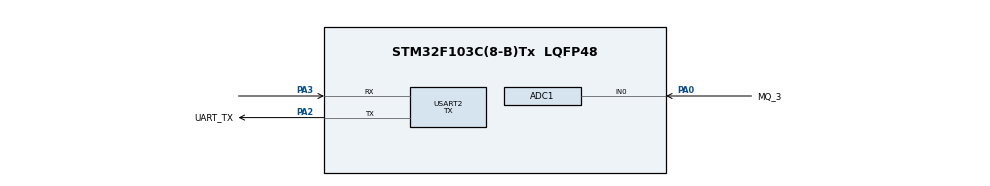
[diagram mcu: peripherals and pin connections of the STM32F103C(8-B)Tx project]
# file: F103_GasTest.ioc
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ADC1.Channel-2\#ChannelRegularConversion=ADC_CHANNEL_0
ADC1.ExternalTrigConv=ADC_EXTERNALTRIGCONV_T3_TRGO
ADC1.NbrOfConversionFlag=1
ADC1.Rank-2\#ChannelRegularConversion=1
ADC1.SamplingTime-2\#ChannelRegularConversion=ADC_SAMPLETIME_28CYCLES_5
ADC1.master=1
Dma.ADC1.1.Direction=DMA_PERIPH_TO_MEMORY
Dma.ADC1.1.Instance=DMA1_Channel1
Dma.ADC1.1.MemDataAlignment=DMA_MDATAALIGN_HALFWORD
Dma.ADC1.1.MemInc=DMA_MINC_ENABLE
Dma.ADC1.1.Mode=DMA_CIRCULAR
Dma.ADC1.1.PeriphDataAlignment=DMA_PDATAALIGN_HALFWORD
Dma.ADC1.1.PeriphInc=DMA_PINC_DISABLE
Dma.ADC1.1.Priority=DMA_PRIORITY_LOW
Dma.Request0=USART2_TX
Dma.Request1=ADC1
Dma.USART2_TX.0.Direction=DMA_MEMORY_TO_PERIPH
Dma.USART2_TX.0.Instance=DMA1_Channel7
Dma.USART2_TX.0.MemDataAlignment=DMA_MDATAALIGN_HALFWORD
Dma.USART2_TX.0.MemInc=DMA_MINC_ENABLE
Dma.USART2_TX.0.Mode=DMA_NORMAL
Dma.USART2_TX.0.PeriphDataAlignment=DMA_PDATAALIGN_BYTE
Dma.USART2_TX.0.PeriphInc=DMA_PINC_DISABLE
Dma.USART2_TX.0.Priority=DMA_PRIORITY_LOW
Mcu.Family=STM32F1
Mcu.Name=STM32F103C(8-B)Tx
Mcu.Package=LQFP48
NVIC.ADC1_2_IRQn=true\:0\:0\:false\:false\:true\:true\:true\:true
NVIC.DMA1_Channel1_IRQn=true\:0\:0\:false\:false\:true\:false\:true\:true
NVIC.DMA1_Channel7_IRQn=true\:0\:0\:false\:false\:true\:false\:true\:true
NVIC.PriorityGroup=NVIC_PRIORITYGROUP_4
NVIC.RCC_IRQn=true\:0\:0\:false\:false\:true\:true\:false\:true
NVIC.TIM3_IRQn=true\:0\:0\:false\:false\:true\:true\:true\:true
NVIC.USART2_IRQn=true\:0\:0\:false\:false\:true\:true\:true\:true
PA0-WKUP.GPIO_Label=MQ_3
PA0-WKUP.Signal=ADCx_IN0
PA13.GPIO_Label=SYS_JTMS
PA13.Mode=Serial_Wire
PA13.Signal=SYS_JTMS-SWDIO
PA14.GPIO_Label=SYS_JTCK
PA14.Mode=Serial_Wire
PA14.Signal=SYS_JTCK-SWCLK
PA2.GPIO_Label=UART_TX
PA2.GPIO_Mode=GPIO_MODE_AF_PP
PA2.Mode=Asynchronous
PA2.Signal=USART2_TX
PA3.Mode=Asynchronous
PA3.Signal=USART2_RX
ProjectManager.HeapSize=0x200
ProjectManager.StackSize=0x400
ProjectManager.TargetToolchain=STM32CubeIDE
RCC.APB1Freq_Value=8000000
RCC.APB2Freq_Value=8000000
SH.ADCx_IN0.0=ADC1_IN0,IN0
TIM3.Period=999
TIM3.Prescaler=71
TIM3.TIM_MasterOutputTrigger=TIM_TRGO_UPDATE
USART2.Mode=MODE_TX
USART2.VirtualMode=VM_ASYNC
VP_TIM3_VS_ClockSourceINT.Mode=Internal
board=custom

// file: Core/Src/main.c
/* USER CODE BEGIN Header */
/**
  ******************************************************************************
  * @file           : main.c
  * @brief          : Main program body
  ******************************************************************************
  * @attention
  *
  * Copyright (c) 2026 STMicroelectronics.
  * All rights reserved.
  *
  * This software is licensed under terms that can be found in the LICENSE file
  * in the root directory of this software component.
  * If no LICENSE file comes with this software, it is provided AS-IS.
  *
  ******************************************************************************
  */
/* USER CODE END Header */
#include "main.h"
#include "string.h"
/* USER CODE BEGIN Includes */
#include <stdint.h>
#include "stdio.h"
/* USER CODE END Includes */

/* USER CODE BEGIN PTD */
#define RB_SIZE			8
#define FRAME_HEADER    0xAA
#define CMD_MQ3_VALUE   0x01
#define MAX_DATA_LEN    8

typedef struct {
	uint16_t 	buf[RB_SIZE];
	uint8_t 	head;
	uint8_t		tail;
	uint8_t		count;
} RingBuffer_t;

/* USER CODE END PTD */

ADC_HandleTypeDef hadc1;
DMA_HandleTypeDef hdma_adc1;

TIM_HandleTypeDef htim3;

UART_HandleTypeDef huart2;
DMA_HandleTypeDef hdma_usart2_tx;

/* USER CODE BEGIN PV */

static volatile uint16_t adcRawValue   = 0;
static volatile uint8_t  newSampleFlag = 0;
static RingBuffer_t adcRing = {0};
static volatile uint8_t uartTxBusy = 0;
/* USER CODE END PV */

void SystemClock_Config(void);
static void MX_GPIO_Init(void);
static void MX_DMA_Init(void);
static void MX_USART2_UART_Init(void);
static void MX_TIM3_Init(void);
static void MX_ADC1_Init(void);

/* USER CODE BEGIN 0 */

/*======================Ring Buffer + Interference Filter============================*/
static void RB_Push(RingBuffer_t *rb, uint16_t value) {
	if (rb->count == RB_SIZE) {
		rb->tail = (rb->tail + 1) % RB_SIZE;
		rb->count--;
	}
	rb->buf[rb->head] = value;
	rb->head = (rb->head + 1) % RB_SIZE;
	rb->count++;
}

static uint16_t RB_Average(RingBuffer_t *rb) {
	if (rb->count == 0)
		return 0;
	uint32_t sum = 0;
	for (uint8_t i = 0; i < rb->count; i++) {
		uint8_t idx = (rb->tail + i) % RB_SIZE;
		sum += rb->buf[idx];
	}
	return (sum / rb->count);
}

/*================ADC + DMA=============================*/
void HAL_ADC_ConvCpltCallback(ADC_HandleTypeDef* hadc){
	if (hadc->Instance == ADC1){
		RB_Push(&adcRing, adcRawValue);
		newSampleFlag = 1;
	}
	HAL_GPIO_TogglePin(GPIOC, GPIO_PIN_13);
}

/* ================= UART TX (DMA) ================= */

static inline uint8_t CalculateCRC(const uint8_t *data, uint8_t len)
{
    uint8_t crc = 0;
    for (uint8_t i = 0; i < len; i++)
        crc ^= data[i];
    return crc;
}

void HAL_UART_TxCpltCallback(UART_HandleTypeDef *huart){
	if(huart->Instance == USART2){
		uartTxBusy = 0;
	}
}

static uint8_t BuildMQ3Frame(uint8_t *txBuf, uint16_t adcValue)
{
    uint8_t idx = 0;
    txBuf[idx++] = FRAME_HEADER;
    txBuf[idx++] = CMD_MQ3_VALUE;
    txBuf[idx++] = 2;
    txBuf[idx++] = adcValue;         /* LSB */
    txBuf[idx++] = (adcValue >> 8) & 0xFF;  /* MSB */

    uint8_t crc = CalculateCRC(&txBuf[1], idx - 1);
    txBuf[idx++] = crc;

    return idx;
}

static void SendMQ3Frame(uint16_t avgValue)
{
    static uint8_t txBuf[6];

    if (uartTxBusy) return;

    uint16_t len =  BuildMQ3Frame(txBuf, avgValue);
    uartTxBusy = 1;
    HAL_UART_Transmit_DMA(&huart2, txBuf, len);
}

/* USER CODE END 0 */

int main(void)
{

  /* MCU Configuration--------------------------------------------------------*/

  /* Reset of all peripherals, Initializes the Flash interface and the Systick. */
  HAL_Init();

  /* Configure the system clock */
  SystemClock_Config();

  /* Initialize all configured peripherals */
  MX_GPIO_Init();
  MX_DMA_Init();
  MX_USART2_UART_Init();
  MX_TIM3_Init();
  MX_ADC1_Init();
  /* USER CODE BEGIN 2 */

	HAL_ADC_Start_DMA(&hadc1, (uint32_t*) &adcRawValue, 1);
	HAL_TIM_Base_Start(&htim3);

  /* USER CODE END 2 */

  /* Infinite loop */
  while (1)
  {

    /* USER CODE BEGIN 3 */
	      static uint32_t sendCounter = 0;

	      if (newSampleFlag)
	      {
	          newSampleFlag = 0;
	          sendCounter++;

	          if (sendCounter >= 10)
	          {
	              sendCounter = 0;
	              uint16_t avg = RB_Average(&adcRing);
	              SendMQ3Frame(avg);
	          }
	      }
	  }

  /* USER CODE END 3 */
}

void SystemClock_Config(void)
{
  RCC_OscInitTypeDef RCC_OscInitStruct = {0};
  RCC_ClkInitTypeDef RCC_ClkInitStruct = {0};
  RCC_PeriphCLKInitTypeDef PeriphClkInit = {0};

  /** Initializes the RCC Oscillators according to the specified parameters
  * in the RCC_OscInitTypeDef structure.
  */
  RCC_OscInitStruct.OscillatorType = RCC_OSCILLATORTYPE_HSI;
  RCC_OscInitStruct.HSIState = RCC_HSI_ON;
  RCC_OscInitStruct.HSICalibrationValue = RCC_HSICALIBRATION_DEFAULT;
  RCC_OscInitStruct.PLL.PLLState = RCC_PLL_NONE;
  if (HAL_RCC_OscConfig(&RCC_OscInitStruct) != HAL_OK)
  {
    Error_Handler();
  }

  /** Initializes the CPU, AHB and APB buses clocks
  */
  RCC_ClkInitStruct.ClockType = RCC_CLOCKTYPE_HCLK|RCC_CLOCKTYPE_SYSCLK
                              |RCC_CLOCKTYPE_PCLK1|RCC_CLOCKTYPE_PCLK2;
  RCC_ClkInitStruct.SYSCLKSource = RCC_SYSCLKSOURCE_HSI;
  RCC_ClkInitStruct.AHBCLKDivider = RCC_SYSCLK_DIV1;
  RCC_ClkInitStruct.APB1CLKDivider = RCC_HCLK_DIV1;
  RCC_ClkInitStruct.APB2CLKDivider = RCC_HCLK_DIV1;

  if (HAL_RCC_ClockConfig(&RCC_ClkInitStruct, FLASH_LATENCY_0) != HAL_OK)
  {
    Error_Handler();
  }
  PeriphClkInit.PeriphClockSelection = RCC_PERIPHCLK_ADC;
  PeriphClkInit.AdcClockSelection = RCC_ADCPCLK2_DIV2;
  if (HAL_RCCEx_PeriphCLKConfig(&PeriphClkInit) != HAL_OK)
  {
    Error_Handler();
  }
}

static void MX_ADC1_Init(void)
{

  ADC_ChannelConfTypeDef sConfig = {0};

  /** Common config
  */
  hadc1.Instance = ADC1;
  hadc1.Init.ScanConvMode = ADC_SCAN_DISABLE;
  hadc1.Init.ContinuousConvMode = DISABLE;
  hadc1.Init.DiscontinuousConvMode = DISABLE;
  hadc1.Init.ExternalTrigConv = ADC_EXTERNALTRIGCONV_T3_TRGO;
  hadc1.Init.DataAlign = ADC_DATAALIGN_RIGHT;
  hadc1.Init.NbrOfConversion = 1;
  if (HAL_ADC_Init(&hadc1) != HAL_OK)
  {
    Error_Handler();
  }

  /** Configure Regular Channel
  */
  sConfig.Channel = ADC_CHANNEL_0;
  sConfig.Rank = ADC_REGULAR_RANK_1;
  sConfig.SamplingTime = ADC_SAMPLETIME_28CYCLES_5;
  if (HAL_ADC_ConfigChannel(&hadc1, &sConfig) != HAL_OK)
  {
    Error_Handler();
  }

}

static void MX_TIM3_Init(void)
{

  TIM_ClockConfigTypeDef sClockSourceConfig = {0};
  TIM_MasterConfigTypeDef sMasterConfig = {0};

  htim3.Instance = TIM3;
  htim3.Init.Prescaler = 71;
  htim3.Init.CounterMode = TIM_COUNTERMODE_UP;
  htim3.Init.Period = 999;
  htim3.Init.ClockDivision = TIM_CLOCKDIVISION_DIV1;
  htim3.Init.AutoReloadPreload = TIM_AUTORELOAD_PRELOAD_DISABLE;
  if (HAL_TIM_Base_Init(&htim3) != HAL_OK)
  {
    Error_Handler();
  }
  sClockSourceConfig.ClockSource = TIM_CLOCKSOURCE_INTERNAL;
  if (HAL_TIM_ConfigClockSource(&htim3, &sClockSourceConfig) != HAL_OK)
  {
    Error_Handler();
  }
  sMasterConfig.MasterOutputTrigger = TIM_TRGO_UPDATE;
  sMasterConfig.MasterSlaveMode = TIM_MASTERSLAVEMODE_DISABLE;
  if (HAL_TIMEx_MasterConfigSynchronization(&htim3, &sMasterConfig) != HAL_OK)
  {
    Error_Handler();
  }

}

static void MX_USART2_UART_Init(void)
{

  huart2.Instance = USART2;
  huart2.Init.BaudRate = 115200;
  huart2.Init.WordLength = UART_WORDLENGTH_8B;
  huart2.Init.StopBits = UART_STOPBITS_1;
  huart2.Init.Parity = UART_PARITY_NONE;
  huart2.Init.Mode = UART_MODE_TX;
  huart2.Init.HwFlowCtl = UART_HWCONTROL_NONE;
  huart2.Init.OverSampling = UART_OVERSAMPLING_16;
  if (HAL_UART_Init(&huart2) != HAL_OK)
  {
    Error_Handler();
  }

}

static void MX_DMA_Init(void)
{

  /* DMA controller clock enable */
  __HAL_RCC_DMA1_CLK_ENABLE();

  /* DMA interrupt init */
  /* DMA1_Channel1_IRQn interrupt configuration */
  HAL_NVIC_SetPriority(DMA1_Channel1_IRQn, 0, 0);
  HAL_NVIC_EnableIRQ(DMA1_Channel1_IRQn);
  /* DMA1_Channel7_IRQn interrupt configuration */
  HAL_NVIC_SetPriority(DMA1_Channel7_IRQn, 0, 0);
  HAL_NVIC_EnableIRQ(DMA1_Channel7_IRQn);

}

static void MX_GPIO_Init(void)
{

  /* GPIO Ports Clock Enable */
  __HAL_RCC_GPIOA_CLK_ENABLE();

  /* USER CODE BEGIN MX_GPIO_Init_2 */
  GPIO_InitTypeDef GPIO_InitStruct = {0};

    __HAL_RCC_GPIOA_CLK_ENABLE();
    __HAL_RCC_GPIOC_CLK_ENABLE();

    /* PA0 - MQ3 analog input */
    GPIO_InitStruct.Pin  = GPIO_PIN_0;
    GPIO_InitStruct.Mode = GPIO_MODE_ANALOG;
    GPIO_InitStruct.Pull = GPIO_NOPULL;
    HAL_GPIO_Init(GPIOA, &GPIO_InitStruct);

    /* PA2 - USART2 TX */
    GPIO_InitStruct.Pin   = GPIO_PIN_2;
    GPIO_InitStruct.Mode  = GPIO_MODE_AF_PP;
    GPIO_InitStruct.Pull  = GPIO_NOPULL;
    GPIO_InitStruct.Speed = GPIO_SPEED_FREQ_HIGH;
    HAL_GPIO_Init(GPIOA, &GPIO_InitStruct);

    /* PC13 - status LED, dùng trong HAL_ADC_ConvCpltCallback */
    GPIO_InitStruct.Pin   = GPIO_PIN_13;
    GPIO_InitStruct.Mode  = GPIO_MODE_OUTPUT_PP;
    GPIO_InitStruct.Pull  = GPIO_NOPULL;
    GPIO_InitStruct.Speed = GPIO_SPEED_FREQ_LOW;
    HAL_GPIO_Init(GPIOC, &GPIO_InitStruct);
  /* USER CODE END MX_GPIO_Init_2 */
}

void Error_Handler(void)
{
  __disable_irq();
  while (1)
  {
  }
}
